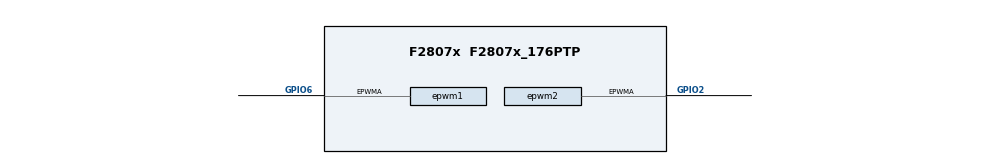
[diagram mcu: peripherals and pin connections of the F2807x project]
/**
 * @cliArgs --device "F2807x" --part "F2807x_176PTP" --package "F2807x_176PTP" --context "system"
 */


/**
 * Import the modules used in this configuration.
 */
const epwm       = scripting.addModule("/driverlib/epwm.js", {}, false);
const epwm1      = epwm.addInstance();
const epwm2      = epwm.addInstance();
const inputxbar  = scripting.addModule("/driverlib/inputxbar.js", {}, false);
const inputxbar1 = inputxbar.addInstance();

/**
 * Write custom configuration values to the imported modules.
 */


epwm1.$name                 = "myEPWM4";
epwm1.useCase               = "CUSTOM";
epwm1.useInterfacePins      = ["EPWM#A"];
epwm1.epwm.$assign          = "EPWM4";
epwm1.epwm.epwmaPin.$assign = "GPIO6";

epwm2.$name                 = "myEPWM2";
epwm2.useCase               = "CUSTOM";
epwm2.useInterfacePins      = ["EPWM#A"];
epwm2.epwm.$assign          = "EPWM2";
epwm2.epwm.epwmaPin.$assign = "GPIO2";

inputxbar1.$name          = "myINPUTXBAR1";
inputxbar1.inputsUsed     = ["inputxbar5Gpio"];
inputxbar1.inputxbar5Gpio = "GPIO2";
